[part 1 of 2: packages /Nexteer/NvMProxy_swc/DataTypes to /Nexteer/NvMProxy_swc/ComponentTypes]
AUTOSAR XML (schema 4-2-1)
package /Nexteer/NvMProxy_swc/DataTypes
  impl type NvM_BlockIdType: category=VALUE, base-type=NvM_BlockIdType, range raw 1..32767
  impl type NvM_RequestResultType: category=VALUE, base-type=NvM_RequestResultType, compu {0=NVM_REQ_OK, 1=NVM_REQ_NOT_OK, 2=NVM_REQ_PENDING, 3=NVM_REQ_INTEGRITY_FAILED, 4=NVM_REQ_BLOCK_SKIPPED, 5=NVM_REQ_NV_INVALIDATED, 6=NVM_REQ_CANCELED, 7=NVM_REQ_REDUNDANCY_FAILED, 8=NVM_REQ_RESTORED_FROM_ROM}
package /Nexteer/NvMProxy_swc/DataTypes/BaseTypes
  base type NvM_BlockIdType: category=FIXED_LENGTH, base-type-size=16, base-type-encoding=NONE, native-declaration=uint16
  base type NvM_RequestResultType: category=FIXED_LENGTH, base-type-size=8, base-type-encoding=NONE, native-declaration=uint8
package /Nexteer/NvMProxy_swc/Interfaces
  5 x client server interface, all with is-service=true:
    NvMAdministration
      operation SetBlockProtection: possible-error=NvMAdministration/E_NOT_OK
        arg ProtectionEnabled_Arg: type=boolean, direction=IN
      error E_NOT_OK: error-code=1
    NvMService_AC3_SRBS
      6 x operation, all with possible-error=NvMService_AC3_SRBS/E_NOT_OK:
        EraseBlock
        GetErrorStatus
          arg ErrorStatus_Arg: type=NvM_RequestResultType, direction=OUT
        InvalidateNvBlock
        ReadBlock
          arg DstPtr_Arg: type=dtRef_VOID, direction=IN
        SetRamBlockStatus
          arg RamBlockStatus_Arg: type=boolean, direction=IN
        WriteBlock
          arg SrcPtr_Arg: type=dtRef_const_VOID, direction=IN
      error E_NOT_OK: error-code=1
    NvMService_AC3_SRBS_Defs
      7 x operation, all with possible-error=NvMService_AC3_SRBS_Defs/E_NOT_OK:
        EraseBlock
        GetErrorStatus
          arg ErrorStatus_Arg: type=NvM_RequestResultType, direction=OUT
        InvalidateNvBlock
        ReadBlock
          arg DstPtr_Arg: type=dtRef_VOID, direction=IN
        RestoreBlockDefaults
          arg DstPtr_Arg: type=dtRef_VOID, direction=IN
        SetRamBlockStatus
          arg RamBlockStatus_Arg: type=boolean, direction=IN
        WriteBlock
          arg SrcPtr_Arg: type=dtRef_const_VOID, direction=IN
      error E_NOT_OK: error-code=1
    NvMService_AC3_SRBS_DS
      8 x operation, all with possible-error=NvMService_AC3_SRBS_DS/E_NOT_OK:
        EraseBlock
        GetDataIndex
          arg DataIndex_Arg: type=uint8, direction=OUT
        GetErrorStatus
          arg ErrorStatus_Arg: type=NvM_RequestResultType, direction=OUT
        InvalidateNvBlock
        ReadBlock
          arg DstPtr_Arg: type=dtRef_VOID, direction=IN
        SetDataIndex
          arg DataIndex_Arg: type=uint8, direction=IN
        SetRamBlockStatus
          arg RamBlockStatus_Arg: type=boolean, direction=IN
        WriteBlock
          arg SrcPtr_Arg: type=dtRef_const_VOID, direction=IN
      error E_NOT_OK: error-code=1
    NvMService_AC3_SRBS_DS_Defs
      9 x operation, all with possible-error=NvMService_AC3_SRBS_DS_Defs/E_NOT_OK:
        EraseBlock
        GetDataIndex
          arg DataIndex_Arg: type=uint8, direction=OUT
        GetErrorStatus
          arg ErrorStatus_Arg: type=NvM_RequestResultType, direction=OUT
        InvalidateNvBlock
        ReadBlock
          arg DstPtr_Arg: type=dtRef_VOID, direction=IN
        RestoreBlockDefaults
          arg DstPtr_Arg: type=dtRef_VOID, direction=IN
        SetDataIndex
          arg DataIndex_Arg: type=uint8, direction=IN
        SetRamBlockStatus
          arg RamBlockStatus_Arg: type=boolean, direction=IN
        WriteBlock
          arg SrcPtr_Arg: type=dtRef_const_VOID, direction=IN
      error E_NOT_OK: error-code=1
package /Nexteer/NvMProxy_swc/ComponentTypes
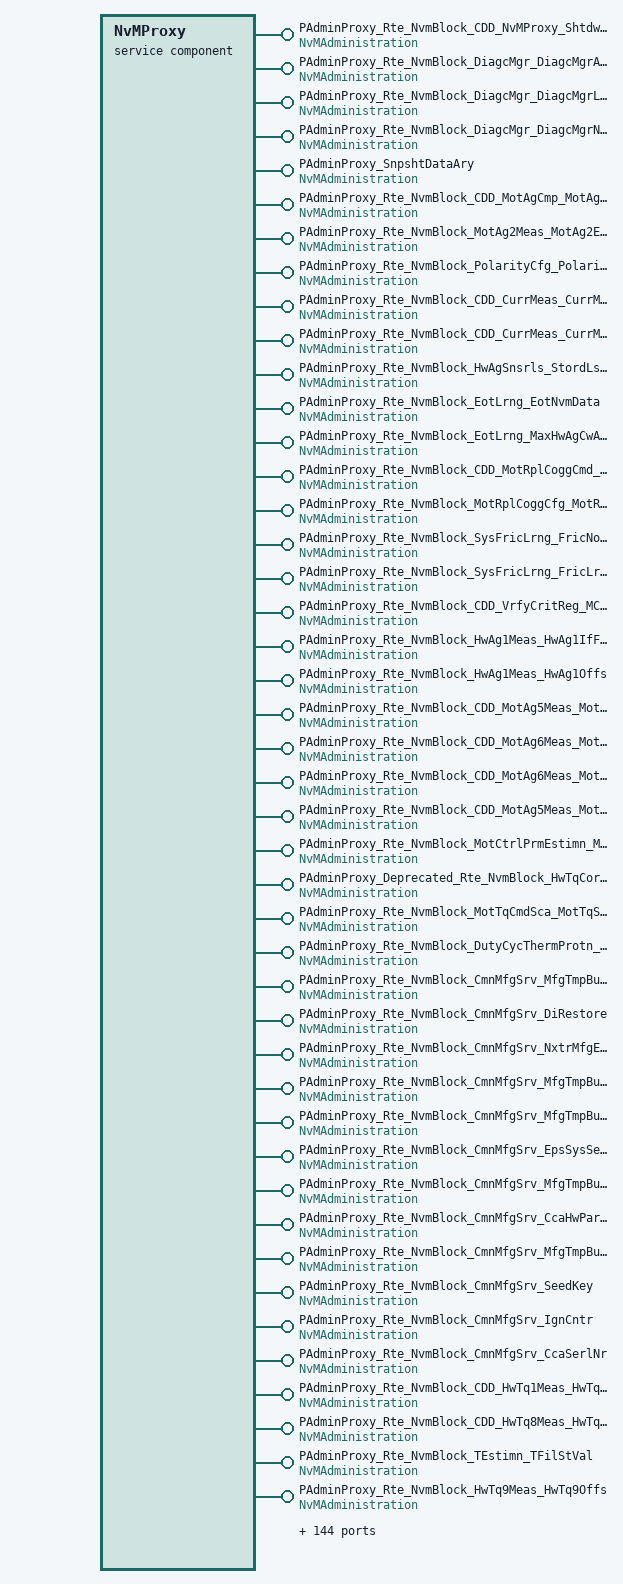
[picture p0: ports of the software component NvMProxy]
  service sw component type NvMProxy
    188 x provide port:
      PAdminProxy_Rte_NvmBlock_CDD_NvMProxy_ShtdwnClsChk: server-com-spec{operation=SetBlockProtection, queue-length=1}, provided-interface=NvMAdministration
      PAdminProxy_Rte_NvmBlock_DiagcMgr_DiagcMgrApplCrc: server-com-spec{operation=SetBlockProtection, queue-length=1}, provided-interface=NvMAdministration
      PAdminProxy_Rte_NvmBlock_DiagcMgr_DiagcMgrLtchCntrAry: server-com-spec{operation=SetBlockProtection, queue-length=1}, provided-interface=NvMAdministration
      PAdminProxy_Rte_NvmBlock_DiagcMgr_DiagcMgrNtcFltAry: server-com-spec{operation=SetBlockProtection, queue-length=1}, provided-interface=NvMAdministration
      PAdminProxy_SnpshtDataAry: server-com-spec{operation=SetBlockProtection, queue-length=1}, provided-interface=NvMAdministration
      PAdminProxy_Rte_NvmBlock_CDD_MotAgCmp_MotAgCmpMotAgBackEmf: server-com-spec{operation=SetBlockProtection, queue-length=1}, provided-interface=NvMAdministration
      PAdminProxy_Rte_NvmBlock_MotAg2Meas_MotAg2EolPrm: server-com-spec{operation=SetBlockProtection, queue-length=1}, provided-interface=NvMAdministration
      PAdminProxy_Rte_NvmBlock_PolarityCfg_PolarityCfgSaved: server-com-spec{operation=SetBlockProtection, queue-length=1}, provided-interface=NvMAdministration
      PAdminProxy_Rte_NvmBlock_CDD_CurrMeas_CurrMeasEolGainCalSetABC: server-com-spec{operation=SetBlockProtection, queue-length=1}, provided-interface=NvMAdministration
      PAdminProxy_Rte_NvmBlock_CDD_CurrMeas_CurrMeasEolOffsCalSetABC: server-com-spec{operation=SetBlockProtection, queue-length=1}, provided-interface=NvMAdministration
      PAdminProxy_Rte_NvmBlock_HwAgSnsrls_StordLstPrm: server-com-spec{operation=SetBlockProtection, queue-length=1}, provided-interface=NvMAdministration
      PAdminProxy_Rte_NvmBlock_EotLrng_EotNvmData: server-com-spec{operation=SetBlockProtection, queue-length=1}, provided-interface=NvMAdministration
      PAdminProxy_Rte_NvmBlock_EotLrng_MaxHwAgCwAndCcw: server-com-spec{operation=SetBlockProtection, queue-length=1}, provided-interface=NvMAdministration
      PAdminProxy_Rte_NvmBlock_CDD_MotRplCoggCmd_MotCoggCmdY: server-com-spec{operation=SetBlockProtection, queue-length=1}, provided-interface=NvMAdministration
      PAdminProxy_Rte_NvmBlock_MotRplCoggCfg_MotRplCoggPrm: server-com-spec{operation=SetBlockProtection, queue-length=1}, provided-interface=NvMAdministration
      PAdminProxy_Rte_NvmBlock_SysFricLrng_FricNonLrngData: server-com-spec{operation=SetBlockProtection, queue-length=1}, provided-interface=NvMAdministration
      PAdminProxy_Rte_NvmBlock_SysFricLrng_FricLrngData: server-com-spec{operation=SetBlockProtection, queue-length=1}, provided-interface=NvMAdministration
      PAdminProxy_Rte_NvmBlock_CDD_VrfyCritReg_MCalReadVrfyCritRegFltNvmInfo: server-com-spec{operation=SetBlockProtection, queue-length=1}, provided-interface=NvMAdministration
      PAdminProxy_Rte_NvmBlock_HwAg1Meas_HwAg1IfFltLtch: server-com-spec{operation=SetBlockProtection, queue-length=1}, provided-interface=NvMAdministration
      PAdminProxy_Rte_NvmBlock_HwAg1Meas_HwAg1Offs: server-com-spec{operation=SetBlockProtection, queue-length=1}, provided-interface=NvMAdministration
      PAdminProxy_Rte_NvmBlock_CDD_MotAg5Meas_MotAg5EolPrm: server-com-spec{operation=SetBlockProtection, queue-length=1}, provided-interface=NvMAdministration
      PAdminProxy_Rte_NvmBlock_CDD_MotAg6Meas_MotAg6StVari: server-com-spec{operation=SetBlockProtection, queue-length=1}, provided-interface=NvMAdministration
      PAdminProxy_Rte_NvmBlock_CDD_MotAg6Meas_MotAg6EolPrm: server-com-spec{operation=SetBlockProtection, queue-length=1}, provided-interface=NvMAdministration
      PAdminProxy_Rte_NvmBlock_CDD_MotAg5Meas_MotAg5StVari: server-com-spec{operation=SetBlockProtection, queue-length=1}, provided-interface=NvMAdministration
      PAdminProxy_Rte_NvmBlock_MotCtrlPrmEstimn_MotPrmNom: server-com-spec{operation=SetBlockProtection, queue-length=1}, provided-interface=NvMAdministration
      PAdminProxy_Deprecated_Rte_NvmBlock_HwTqCorrln_HwTqChACmnModCmpLpFilSt: server-com-spec{operation=SetBlockProtection, queue-length=1}, provided-interface=NvMAdministration
      PAdminProxy_Rte_NvmBlock_MotTqCmdSca_MotTqScaFac: server-com-spec{operation=SetBlockProtection, queue-length=1}, provided-interface=NvMAdministration
      PAdminProxy_Rte_NvmBlock_DutyCycThermProtn_FilStVal: server-com-spec{operation=SetBlockProtection, queue-length=1}, provided-interface=NvMAdministration
      PAdminProxy_Rte_NvmBlock_CmnMfgSrv_MfgTmpBuf1: server-com-spec{operation=SetBlockProtection, queue-length=1}, provided-interface=NvMAdministration
      PAdminProxy_Rte_NvmBlock_CmnMfgSrv_DiRestore: server-com-spec{operation=SetBlockProtection, queue-length=1}, provided-interface=NvMAdministration
      PAdminProxy_Rte_NvmBlock_CmnMfgSrv_NxtrMfgEnaCntr: server-com-spec{operation=SetBlockProtection, queue-length=1}, provided-interface=NvMAdministration
      PAdminProxy_Rte_NvmBlock_CmnMfgSrv_MfgTmpBuf0: server-com-spec{operation=SetBlockProtection, queue-length=1}, provided-interface=NvMAdministration
      PAdminProxy_Rte_NvmBlock_CmnMfgSrv_MfgTmpBuf3: server-com-spec{operation=SetBlockProtection, queue-length=1}, provided-interface=NvMAdministration
      PAdminProxy_Rte_NvmBlock_CmnMfgSrv_EpsSysSerlNr: server-com-spec{operation=SetBlockProtection, queue-length=1}, provided-interface=NvMAdministration
      PAdminProxy_Rte_NvmBlock_CmnMfgSrv_MfgTmpBuf2: server-com-spec{operation=SetBlockProtection, queue-length=1}, provided-interface=NvMAdministration
      PAdminProxy_Rte_NvmBlock_CmnMfgSrv_CcaHwPartNr: server-com-spec{operation=SetBlockProtection, queue-length=1}, provided-interface=NvMAdministration
      PAdminProxy_Rte_NvmBlock_CmnMfgSrv_MfgTmpBuf4: server-com-spec{operation=SetBlockProtection, queue-length=1}, provided-interface=NvMAdministration
      PAdminProxy_Rte_NvmBlock_CmnMfgSrv_SeedKey: server-com-spec{operation=SetBlockProtection, queue-length=1}, provided-interface=NvMAdministration
      PAdminProxy_Rte_NvmBlock_CmnMfgSrv_IgnCntr: server-com-spec{operation=SetBlockProtection, queue-length=1}, provided-interface=NvMAdministration
      PAdminProxy_Rte_NvmBlock_CmnMfgSrv_CcaSerlNr: server-com-spec{operation=SetBlockProtection, queue-length=1}, provided-interface=NvMAdministration
      PAdminProxy_Rte_NvmBlock_CDD_HwTq1Meas_HwTq1Offs: server-com-spec{operation=SetBlockProtection, queue-length=1}, provided-interface=NvMAdministration
      PAdminProxy_Rte_NvmBlock_CDD_HwTq8Meas_HwTq8Offs: server-com-spec{operation=SetBlockProtection, queue-length=1}, provided-interface=NvMAdministration
      PAdminProxy_Rte_NvmBlock_TEstimn_TFilStVal: server-com-spec{operation=SetBlockProtection, queue-length=1}, provided-interface=NvMAdministration
      PAdminProxy_Rte_NvmBlock_HwTq9Meas_HwTq9Offs: server-com-spec{operation=SetBlockProtection, queue-length=1}, provided-interface=NvMAdministration
      PAdminProxy_Rte_NvmBlock_HwTq10Meas_HwTq10Offs: server-com-spec{operation=SetBlockProtection, queue-length=1}, provided-interface=NvMAdministration
      PAdminProxy_Rte_NvmBlock_CustDiag_DidDE04: server-com-spec{operation=SetBlockProtection, queue-length=1}, provided-interface=NvMAdministration
      PAdminProxy_Rte_NvmBlock_CustDiag_DidDE02: server-com-spec{operation=SetBlockProtection, queue-length=1}, provided-interface=NvMAdministration
      PAdminProxy_Rte_NvmBlock_CustDiag_Did3003: server-com-spec{operation=SetBlockProtection, queue-length=1}, provided-interface=NvMAdministration
      PAdminProxy_Rte_NvmBlock_CustDiag_DidDE01: server-com-spec{operation=SetBlockProtection, queue-length=1}, provided-interface=NvMAdministration
      PAdminProxy_Rte_NvmBlock_CustDiag_DidEE01: server-com-spec{operation=SetBlockProtection, queue-length=1}, provided-interface=NvMAdministration
      PAdminProxy_Rte_NvmBlock_CustDiag_DidDE03: server-com-spec{operation=SetBlockProtection, queue-length=1}, provided-interface=NvMAdministration
      PAdminProxy_Rte_NvmBlock_CustDiag_DidDE00: server-com-spec{operation=SetBlockProtection, queue-length=1}, provided-interface=NvMAdministration
      PAdminProxy_Rte_NvmBlock_CustDiag_DidF113: server-com-spec{operation=SetBlockProtection, queue-length=1}, provided-interface=NvMAdministration
      PAdminProxy_Rte_NvmBlock_CustDiag_DidEE02: server-com-spec{operation=SetBlockProtection, queue-length=1}, provided-interface=NvMAdministration
      PAdminProxy_Rte_NvmBlock_CustDiag_DidF111: server-com-spec{operation=SetBlockProtection, queue-length=1}, provided-interface=NvMAdministration
      PAdminProxy_Rte_NvmBlock_FordHwAgArbn_PrevIgnCycVal: server-com-spec{operation=SetBlockProtection, queue-length=1}, provided-interface=NvMAdministration
      PAdminProxy_Rte_NvmBlock_FordHwAgArbn_NonAbsOffsVldFlg: server-com-spec{operation=SetBlockProtection, queue-length=1}, provided-interface=NvMAdministration
      PAdminProxy_Rte_NvmBlock_FordHwAgArbn_NonAbsOffs: server-com-spec{operation=SetBlockProtection, queue-length=1}, provided-interface=NvMAdministration
      PAdminProxy_Rte_NvmBlock_FordVehSpdArbn_FordVehTireCircum: server-com-spec{operation=SetBlockProtection, queue-length=1}, provided-interface=NvMAdministration
      PAdminProxy_Rte_NvmBlock_CustDiag_DidEE87: server-com-spec{operation=SetBlockProtection, queue-length=1}, provided-interface=NvMAdministration
      PAdminProxy_Rte_NvmBlock_CustDiag_DidF110: server-com-spec{operation=SetBlockProtection, queue-length=1}, provided-interface=NvMAdministration
      PAdminProxy_Rte_NvmBlock_CustDiag_DidF163: server-com-spec{operation=SetBlockProtection, queue-length=1}, provided-interface=NvMAdministration
      PAdminProxy_Rte_NvmBlock_CustDiag_DidF18C: server-com-spec{operation=SetBlockProtection, queue-length=1}, provided-interface=NvMAdministration
      PAdminProxy_Rte_NvmBlock_CustDiag_Did205B: server-com-spec{operation=SetBlockProtection, queue-length=1}, provided-interface=NvMAdministration
      PAdminProxy_Rte_NvmBlock_CustDiag_DidEE00: server-com-spec{operation=SetBlockProtection, queue-length=1}, provided-interface=NvMAdministration
      PAdminProxy_Rte_NvmBlock_CustDiag_DidDE05: server-com-spec{operation=SetBlockProtection, queue-length=1}, provided-interface=NvMAdministration
      PAdminProxy_Rte_NvmBlock_CustDiag_DidEE40: server-com-spec{operation=SetBlockProtection, queue-length=1}, provided-interface=NvMAdministration
      PAdminProxy_Rte_NvmBlock_CustDiag_DidF18A: server-com-spec{operation=SetBlockProtection, queue-length=1}, provided-interface=NvMAdministration
      PAdminProxy_Rte_NvmBlock_CustDiag_DidEE84: server-com-spec{operation=SetBlockProtection, queue-length=1}, provided-interface=NvMAdministration
      PAdminProxy_Rte_NvmBlock_CustDiag_DidF15F: server-com-spec{operation=SetBlockProtection, queue-length=1}, provided-interface=NvMAdministration
      PAdminProxy_Rte_NvmBlock_CustDiag_DidF166: server-com-spec{operation=SetBlockProtection, queue-length=1}, provided-interface=NvMAdministration
      PAdminProxy_Rte_NvmBlock_CustDiag_DidF162: server-com-spec{operation=SetBlockProtection, queue-length=1}, provided-interface=NvMAdministration
      PAdminProxy_Rte_NvmBlock_CustDiag_DidEE82: server-com-spec{operation=SetBlockProtection, queue-length=1}, provided-interface=NvMAdministration
      PAdminProxy_Rte_NvmBlock_CustDiag_DidEE86: server-com-spec{operation=SetBlockProtection, queue-length=1}, provided-interface=NvMAdministration
      PAdminProxy_Rte_NvmBlock_CustDiag_DidEE88: server-com-spec{operation=SetBlockProtection, queue-length=1}, provided-interface=NvMAdministration
      PAdminProxy_Rte_NvmBlock_CustDiag_DidEE85: server-com-spec{operation=SetBlockProtection, queue-length=1}, provided-interface=NvMAdministration
      PAdminProxy_Rte_NvmBlock_CustDiag_Did205A: server-com-spec{operation=SetBlockProtection, queue-length=1}, provided-interface=NvMAdministration
      PAdminProxy_Rte_NvmBlock_CustDiag_DidEE81: server-com-spec{operation=SetBlockProtection, queue-length=1}, provided-interface=NvMAdministration
      PAdminProxy_Rte_NvmBlock_CustDiag_Did301A: server-com-spec{operation=SetBlockProtection, queue-length=1}, provided-interface=NvMAdministration
      PAdminProxy_Rte_NvmBlock_CustDiag_DidEE41: server-com-spec{operation=SetBlockProtection, queue-length=1}, provided-interface=NvMAdministration
      PAdminProxy_Rte_NvmBlock_CustDiag_DidEE83: server-com-spec{operation=SetBlockProtection, queue-length=1}, provided-interface=NvMAdministration
      PAdminProxy_Rte_NvmBlock_CustDiag_DidEED0: server-com-spec{operation=SetBlockProtection, queue-length=1}, provided-interface=NvMAdministration
      PAdminProxy_Rte_NvmBlock_CustDiag_DidEE21: server-com-spec{operation=SetBlockProtection, queue-length=1}, provided-interface=NvMAdministration
      PAdminProxy_Rte_NvmBlock_CustDiag_Did630F: server-com-spec{operation=SetBlockProtection, queue-length=1}, provided-interface=NvMAdministration
      PAdminProxy_Rte_NvmBlock_CustDiag_DidEE22: server-com-spec{operation=SetBlockProtection, queue-length=1}, provided-interface=NvMAdministration
      PAdminProxy_Rte_NvmBlock_CustDiag_DidEE23: server-com-spec{operation=SetBlockProtection, queue-length=1}, provided-interface=NvMAdministration
      PAdminProxy_Rte_NvmBlock_CustDiag_Did630FChk: server-com-spec{operation=SetBlockProtection, queue-length=1}, provided-interface=NvMAdministration
      PAdminProxy_Rte_NvmBlock_CustDiag_DidF190: server-com-spec{operation=SetBlockProtection, queue-length=1}, provided-interface=NvMAdministration
      PAdminProxy_Rte_NvmBlock_StackMeas_StackMeasRes: server-com-spec{operation=SetBlockProtection, queue-length=1}, provided-interface=NvMAdministration
      PAdminProxy_Rte_NvmBlock_StackMeas_StackMeasApplCrc: server-com-spec{operation=SetBlockProtection, queue-length=1}, provided-interface=NvMAdministration
      PAdminProxy_Rte_NvmBlock_CDD_FordBlaBoxIfCmp1_LaneAssi: server-com-spec{operation=SetBlockProtection, queue-length=1}, provided-interface=NvMAdministration
      PAdminProxy_Rte_NvmBlock_CDD_FordBlaBoxIfCmp1_ActvNiblCtrl: server-com-spec{operation=SetBlockProtection, queue-length=1}, provided-interface=NvMAdministration
      PAdminProxy_Rte_NvmBlock_CDD_FordBlaBoxIfCmp1_TrlrBackupAssi: server-com-spec{operation=SetBlockProtection, queue-length=1}, provided-interface=NvMAdministration
      PAdminProxy_Rte_NvmBlock_CDD_FordBlaBoxIfCmp1_PullDriftCmp: server-com-spec{operation=SetBlockProtection, queue-length=1}, provided-interface=NvMAdministration
      PSProxy_Rte_NvmBlock_DiagcMgr_DiagcMgrApplCrc: provided-interface=NvMService_AC3_SRBS_Defs
        provided-com-specs:
          operation=NvMService_AC3_SRBS_Defs/EraseBlock, queue-length=1
          operation=NvMService_AC3_SRBS_Defs/GetErrorStatus, queue-length=1
          operation=NvMService_AC3_SRBS_Defs/InvalidateNvBlock, queue-length=1
          operation=NvMService_AC3_SRBS_Defs/ReadBlock, queue-length=1
          operation=NvMService_AC3_SRBS_Defs/RestoreBlockDefaults, queue-length=1
          operation=NvMService_AC3_SRBS_Defs/SetRamBlockStatus, queue-length=1
          operation=NvMService_AC3_SRBS_Defs/WriteBlock, queue-length=1
      PSProxy_Rte_NvmBlock_CDD_MotAgCmp_MotAgCmpMotAgBackEmf: provided-interface=NvMService_AC3_SRBS_Defs
        provided-com-specs:
          operation=NvMService_AC3_SRBS_Defs/EraseBlock, queue-length=1
          operation=NvMService_AC3_SRBS_Defs/GetErrorStatus, queue-length=1
          operation=NvMService_AC3_SRBS_Defs/InvalidateNvBlock, queue-length=1
          operation=NvMService_AC3_SRBS_Defs/ReadBlock, queue-length=1
          operation=NvMService_AC3_SRBS_Defs/RestoreBlockDefaults, queue-length=1
          operation=NvMService_AC3_SRBS_Defs/SetRamBlockStatus, queue-length=1
          operation=NvMService_AC3_SRBS_Defs/WriteBlock, queue-length=1
      PSProxy_Rte_NvmBlock_MotAg2Meas_MotAg2EolPrm: provided-interface=NvMService_AC3_SRBS_Defs
        provided-com-specs:
          operation=NvMService_AC3_SRBS_Defs/EraseBlock, queue-length=1
          operation=NvMService_AC3_SRBS_Defs/GetErrorStatus, queue-length=1
          operation=NvMService_AC3_SRBS_Defs/InvalidateNvBlock, queue-length=1
          operation=NvMService_AC3_SRBS_Defs/ReadBlock, queue-length=1
          operation=NvMService_AC3_SRBS_Defs/RestoreBlockDefaults, queue-length=1
          operation=NvMService_AC3_SRBS_Defs/SetRamBlockStatus, queue-length=1
          operation=NvMService_AC3_SRBS_Defs/WriteBlock, queue-length=1
      PSProxy_Rte_NvmBlock_PolarityCfg_PolarityCfgSaved: provided-interface=NvMService_AC3_SRBS_Defs
        provided-com-specs:
          operation=NvMService_AC3_SRBS_Defs/EraseBlock, queue-length=1
          operation=NvMService_AC3_SRBS_Defs/GetErrorStatus, queue-length=1
          operation=NvMService_AC3_SRBS_Defs/InvalidateNvBlock, queue-length=1
          operation=NvMService_AC3_SRBS_Defs/ReadBlock, queue-length=1
          operation=NvMService_AC3_SRBS_Defs/RestoreBlockDefaults, queue-length=1
          operation=NvMService_AC3_SRBS_Defs/SetRamBlockStatus, queue-length=1
          operation=NvMService_AC3_SRBS_Defs/WriteBlock, queue-length=1
      PSProxy_Rte_NvmBlock_CDD_CurrMeas_CurrMeasEolGainCalSetABC: provided-interface=NvMService_AC3_SRBS_Defs
        provided-com-specs:
          operation=NvMService_AC3_SRBS_Defs/EraseBlock, queue-length=1
          operation=NvMService_AC3_SRBS_Defs/GetErrorStatus, queue-length=1
          operation=NvMService_AC3_SRBS_Defs/InvalidateNvBlock, queue-length=1
          operation=NvMService_AC3_SRBS_Defs/ReadBlock, queue-length=1
          operation=NvMService_AC3_SRBS_Defs/RestoreBlockDefaults, queue-length=1
          operation=NvMService_AC3_SRBS_Defs/SetRamBlockStatus, queue-length=1
          operation=NvMService_AC3_SRBS_Defs/WriteBlock, queue-length=1
      PSProxy_Rte_NvmBlock_CDD_CurrMeas_CurrMeasEolOffsCalSetABC: provided-interface=NvMService_AC3_SRBS_Defs
        provided-com-specs:
          operation=NvMService_AC3_SRBS_Defs/EraseBlock, queue-length=1
          operation=NvMService_AC3_SRBS_Defs/GetErrorStatus, queue-length=1
          operation=NvMService_AC3_SRBS_Defs/InvalidateNvBlock, queue-length=1
          operation=NvMService_AC3_SRBS_Defs/ReadBlock, queue-length=1
          operation=NvMService_AC3_SRBS_Defs/RestoreBlockDefaults, queue-length=1
          operation=NvMService_AC3_SRBS_Defs/SetRamBlockStatus, queue-length=1
          operation=NvMService_AC3_SRBS_Defs/WriteBlock, queue-length=1
      PSProxy_Rte_NvmBlock_HwAgSnsrls_StordLstPrm: provided-interface=NvMService_AC3_SRBS_Defs
        provided-com-specs:
          operation=NvMService_AC3_SRBS_Defs/EraseBlock, queue-length=1
          operation=NvMService_AC3_SRBS_Defs/GetErrorStatus, queue-length=1
          operation=NvMService_AC3_SRBS_Defs/InvalidateNvBlock, queue-length=1
          operation=NvMService_AC3_SRBS_Defs/ReadBlock, queue-length=1
          operation=NvMService_AC3_SRBS_Defs/RestoreBlockDefaults, queue-length=1
          operation=NvMService_AC3_SRBS_Defs/SetRamBlockStatus, queue-length=1
          operation=NvMService_AC3_SRBS_Defs/WriteBlock, queue-length=1
      PSProxy_Rte_NvmBlock_SysFricLrng_FricNonLrngData: provided-interface=NvMService_AC3_SRBS_Defs
        provided-com-specs:
          operation=NvMService_AC3_SRBS_Defs/EraseBlock, queue-length=1
          operation=NvMService_AC3_SRBS_Defs/GetErrorStatus, queue-length=1
          operation=NvMService_AC3_SRBS_Defs/InvalidateNvBlock, queue-length=1
          operation=NvMService_AC3_SRBS_Defs/ReadBlock, queue-length=1
          operation=NvMService_AC3_SRBS_Defs/RestoreBlockDefaults, queue-length=1
          operation=NvMService_AC3_SRBS_Defs/SetRamBlockStatus, queue-length=1
          operation=NvMService_AC3_SRBS_Defs/WriteBlock, queue-length=1
      PSProxy_Rte_NvmBlock_SysFricLrng_FricLrngData: provided-interface=NvMService_AC3_SRBS_Defs
        provided-com-specs:
          operation=NvMService_AC3_SRBS_Defs/EraseBlock, queue-length=1
          operation=NvMService_AC3_SRBS_Defs/GetErrorStatus, queue-length=1
          operation=NvMService_AC3_SRBS_Defs/InvalidateNvBlock, queue-length=1
          operation=NvMService_AC3_SRBS_Defs/ReadBlock, queue-length=1
          operation=NvMService_AC3_SRBS_Defs/RestoreBlockDefaults, queue-length=1
          operation=NvMService_AC3_SRBS_Defs/SetRamBlockStatus, queue-length=1
          operation=NvMService_AC3_SRBS_Defs/WriteBlock, queue-length=1
      PSProxy_Rte_NvmBlock_CmnMfgSrv_NxtrMfgEnaCntr: provided-interface=NvMService_AC3_SRBS_Defs
        provided-com-specs:
          operation=NvMService_AC3_SRBS_Defs/EraseBlock, queue-length=1
          operation=NvMService_AC3_SRBS_Defs/GetErrorStatus, queue-length=1
          operation=NvMService_AC3_SRBS_Defs/InvalidateNvBlock, queue-length=1
          operation=NvMService_AC3_SRBS_Defs/ReadBlock, queue-length=1
          operation=NvMService_AC3_SRBS_Defs/RestoreBlockDefaults, queue-length=1
          operation=NvMService_AC3_SRBS_Defs/SetRamBlockStatus, queue-length=1
          operation=NvMService_AC3_SRBS_Defs/WriteBlock, queue-length=1
      PSProxy_Rte_NvmBlock_CmnMfgSrv_SeedKey: provided-interface=NvMService_AC3_SRBS_Defs
        provided-com-specs:
          operation=NvMService_AC3_SRBS_Defs/EraseBlock, queue-length=1
          operation=NvMService_AC3_SRBS_Defs/GetErrorStatus, queue-length=1
          operation=NvMService_AC3_SRBS_Defs/InvalidateNvBlock, queue-length=1
          operation=NvMService_AC3_SRBS_Defs/ReadBlock, queue-length=1
          operation=NvMService_AC3_SRBS_Defs/RestoreBlockDefaults, queue-length=1
          operation=NvMService_AC3_SRBS_Defs/SetRamBlockStatus, queue-length=1
          operation=NvMService_AC3_SRBS_Defs/WriteBlock, queue-length=1
      PSProxy_Rte_NvmBlock_CmnMfgSrv_IgnCntr: provided-interface=NvMService_AC3_SRBS_Defs
        provided-com-specs:
          operation=NvMService_AC3_SRBS_Defs/EraseBlock, queue-length=1
          operation=NvMService_AC3_SRBS_Defs/GetErrorStatus, queue-length=1
          operation=NvMService_AC3_SRBS_Defs/InvalidateNvBlock, queue-length=1
          operation=NvMService_AC3_SRBS_Defs/ReadBlock, queue-length=1
          operation=NvMService_AC3_SRBS_Defs/RestoreBlockDefaults, queue-length=1
          operation=NvMService_AC3_SRBS_Defs/SetRamBlockStatus, queue-length=1
          operation=NvMService_AC3_SRBS_Defs/WriteBlock, queue-length=1
      PSProxy_Rte_NvmBlock_CDD_HwTq1Meas_HwTq1Offs: provided-interface=NvMService_AC3_SRBS_Defs
        provided-com-specs:
          operation=NvMService_AC3_SRBS_Defs/EraseBlock, queue-length=1
          operation=NvMService_AC3_SRBS_Defs/GetErrorStatus, queue-length=1
          operation=NvMService_AC3_SRBS_Defs/InvalidateNvBlock, queue-length=1
          operation=NvMService_AC3_SRBS_Defs/ReadBlock, queue-length=1
          operation=NvMService_AC3_SRBS_Defs/RestoreBlockDefaults, queue-length=1
          operation=NvMService_AC3_SRBS_Defs/SetRamBlockStatus, queue-length=1
          operation=NvMService_AC3_SRBS_Defs/WriteBlock, queue-length=1
      PSProxy_Rte_NvmBlock_CDD_HwTq8Meas_HwTq8Offs: provided-interface=NvMService_AC3_SRBS_Defs
        provided-com-specs:
          operation=NvMService_AC3_SRBS_Defs/EraseBlock, queue-length=1
          operation=NvMService_AC3_SRBS_Defs/GetErrorStatus, queue-length=1
          operation=NvMService_AC3_SRBS_Defs/InvalidateNvBlock, queue-length=1
          operation=NvMService_AC3_SRBS_Defs/ReadBlock, queue-length=1
          operation=NvMService_AC3_SRBS_Defs/RestoreBlockDefaults, queue-length=1
          operation=NvMService_AC3_SRBS_Defs/SetRamBlockStatus, queue-length=1
          operation=NvMService_AC3_SRBS_Defs/WriteBlock, queue-length=1
      PSProxy_Rte_NvmBlock_CustDiag_DidDE04: provided-interface=NvMService_AC3_SRBS_Defs
        provided-com-specs:
          operation=NvMService_AC3_SRBS_Defs/EraseBlock, queue-length=1
          operation=NvMService_AC3_SRBS_Defs/GetErrorStatus, queue-length=1
          operation=NvMService_AC3_SRBS_Defs/InvalidateNvBlock, queue-length=1
          operation=NvMService_AC3_SRBS_Defs/ReadBlock, queue-length=1
          operation=NvMService_AC3_SRBS_Defs/RestoreBlockDefaults, queue-length=1
          operation=NvMService_AC3_SRBS_Defs/SetRamBlockStatus, queue-length=1
          operation=NvMService_AC3_SRBS_Defs/WriteBlock, queue-length=1
      PSProxy_Rte_NvmBlock_CustDiag_DidDE02: provided-interface=NvMService_AC3_SRBS_Defs
        provided-com-specs:
          operation=NvMService_AC3_SRBS_Defs/EraseBlock, queue-length=1
          operation=NvMService_AC3_SRBS_Defs/GetErrorStatus, queue-length=1
          operation=NvMService_AC3_SRBS_Defs/InvalidateNvBlock, queue-length=1
          operation=NvMService_AC3_SRBS_Defs/ReadBlock, queue-length=1
          operation=NvMService_AC3_SRBS_Defs/RestoreBlockDefaults, queue-length=1
          operation=NvMService_AC3_SRBS_Defs/SetRamBlockStatus, queue-length=1
          operation=NvMService_AC3_SRBS_Defs/WriteBlock, queue-length=1
      PSProxy_Rte_NvmBlock_CustDiag_Did3003: provided-interface=NvMService_AC3_SRBS_Defs
        provided-com-specs:
          operation=NvMService_AC3_SRBS_Defs/EraseBlock, queue-length=1
          operation=NvMService_AC3_SRBS_Defs/GetErrorStatus, queue-length=1
          operation=NvMService_AC3_SRBS_Defs/InvalidateNvBlock, queue-length=1
          operation=NvMService_AC3_SRBS_Defs/ReadBlock, queue-length=1
          operation=NvMService_AC3_SRBS_Defs/RestoreBlockDefaults, queue-length=1
          operation=NvMService_AC3_SRBS_Defs/SetRamBlockStatus, queue-length=1
          operation=NvMService_AC3_SRBS_Defs/WriteBlock, queue-length=1
      PSProxy_Rte_NvmBlock_CustDiag_DidDE01: provided-interface=NvMService_AC3_SRBS_Defs
        provided-com-specs:
          operation=NvMService_AC3_SRBS_Defs/EraseBlock, queue-length=1
          operation=NvMService_AC3_SRBS_Defs/GetErrorStatus, queue-length=1
          operation=NvMService_AC3_SRBS_Defs/InvalidateNvBlock, queue-length=1
          operation=NvMService_AC3_SRBS_Defs/ReadBlock, queue-length=1
          operation=NvMService_AC3_SRBS_Defs/RestoreBlockDefaults, queue-length=1
          operation=NvMService_AC3_SRBS_Defs/SetRamBlockStatus, queue-length=1
          operation=NvMService_AC3_SRBS_Defs/WriteBlock, queue-length=1
      PSProxy_Rte_NvmBlock_CustDiag_DidEE01: provided-interface=NvMService_AC3_SRBS_Defs
        provided-com-specs:
          operation=NvMService_AC3_SRBS_Defs/EraseBlock, queue-length=1
          operation=NvMService_AC3_SRBS_Defs/GetErrorStatus, queue-length=1
          operation=NvMService_AC3_SRBS_Defs/InvalidateNvBlock, queue-length=1
          operation=NvMService_AC3_SRBS_Defs/ReadBlock, queue-length=1
          operation=NvMService_AC3_SRBS_Defs/RestoreBlockDefaults, queue-length=1
          operation=NvMService_AC3_SRBS_Defs/SetRamBlockStatus, queue-length=1
          operation=NvMService_AC3_SRBS_Defs/WriteBlock, queue-length=1
      PSProxy_Rte_NvmBlock_CustDiag_DidDE03: provided-interface=NvMService_AC3_SRBS_Defs
        provided-com-specs:
          operation=NvMService_AC3_SRBS_Defs/EraseBlock, queue-length=1
          operation=NvMService_AC3_SRBS_Defs/GetErrorStatus, queue-length=1
          operation=NvMService_AC3_SRBS_Defs/InvalidateNvBlock, queue-length=1
          operation=NvMService_AC3_SRBS_Defs/ReadBlock, queue-length=1
          operation=NvMService_AC3_SRBS_Defs/RestoreBlockDefaults, queue-length=1
          operation=NvMService_AC3_SRBS_Defs/SetRamBlockStatus, queue-length=1
          operation=NvMService_AC3_SRBS_Defs/WriteBlock, queue-length=1
      PSProxy_Rte_NvmBlock_CustDiag_DidDE00: provided-interface=NvMService_AC3_SRBS_Defs
        provided-com-specs:
          operation=NvMService_AC3_SRBS_Defs/EraseBlock, queue-length=1
          operation=NvMService_AC3_SRBS_Defs/GetErrorStatus, queue-length=1
          operation=NvMService_AC3_SRBS_Defs/InvalidateNvBlock, queue-length=1
          operation=NvMService_AC3_SRBS_Defs/ReadBlock, queue-length=1
          operation=NvMService_AC3_SRBS_Defs/RestoreBlockDefaults, queue-length=1
          operation=NvMService_AC3_SRBS_Defs/SetRamBlockStatus, queue-length=1
          operation=NvMService_AC3_SRBS_Defs/WriteBlock, queue-length=1
      PSProxy_Rte_NvmBlock_CustDiag_DidF113: provided-interface=NvMService_AC3_SRBS_Defs
        provided-com-specs:
          operation=NvMService_AC3_SRBS_Defs/EraseBlock, queue-length=1
          operation=NvMService_AC3_SRBS_Defs/GetErrorStatus, queue-length=1
          operation=NvMService_AC3_SRBS_Defs/InvalidateNvBlock, queue-length=1
          operation=NvMService_AC3_SRBS_Defs/ReadBlock, queue-length=1
          operation=NvMService_AC3_SRBS_Defs/RestoreBlockDefaults, queue-length=1
          operation=NvMService_AC3_SRBS_Defs/SetRamBlockStatus, queue-length=1
          operation=NvMService_AC3_SRBS_Defs/WriteBlock, queue-length=1
      PSProxy_Rte_NvmBlock_CustDiag_DidEE02: provided-interface=NvMService_AC3_SRBS_Defs
        provided-com-specs:
          operation=NvMService_AC3_SRBS_Defs/EraseBlock, queue-length=1
          operation=NvMService_AC3_SRBS_Defs/GetErrorStatus, queue-length=1
          operation=NvMService_AC3_SRBS_Defs/InvalidateNvBlock, queue-length=1
          operation=NvMService_AC3_SRBS_Defs/ReadBlock, queue-length=1
          operation=NvMService_AC3_SRBS_Defs/RestoreBlockDefaults, queue-length=1
          operation=NvMService_AC3_SRBS_Defs/SetRamBlockStatus, queue-length=1
          operation=NvMService_AC3_SRBS_Defs/WriteBlock, queue-length=1
      PSProxy_Rte_NvmBlock_CustDiag_DidF111: provided-interface=NvMService_AC3_SRBS_Defs
        provided-com-specs:
          operation=NvMService_AC3_SRBS_Defs/EraseBlock, queue-length=1
          operation=NvMService_AC3_SRBS_Defs/GetErrorStatus, queue-length=1
          operation=NvMService_AC3_SRBS_Defs/InvalidateNvBlock, queue-length=1
          operation=NvMService_AC3_SRBS_Defs/ReadBlock, queue-length=1
          operation=NvMService_AC3_SRBS_Defs/RestoreBlockDefaults, queue-length=1
          operation=NvMService_AC3_SRBS_Defs/SetRamBlockStatus, queue-length=1
          operation=NvMService_AC3_SRBS_Defs/WriteBlock, queue-length=1
      PSProxy_Rte_NvmBlock_FordHwAgArbn_PrevIgnCycVal: provided-interface=NvMService_AC3_SRBS_Defs
        provided-com-specs:
          operation=NvMService_AC3_SRBS_Defs/EraseBlock, queue-length=1
          operation=NvMService_AC3_SRBS_Defs/GetErrorStatus, queue-length=1
          operation=NvMService_AC3_SRBS_Defs/InvalidateNvBlock, queue-length=1
          operation=NvMService_AC3_SRBS_Defs/ReadBlock, queue-length=1
          operation=NvMService_AC3_SRBS_Defs/RestoreBlockDefaults, queue-length=1
          operation=NvMService_AC3_SRBS_Defs/SetRamBlockStatus, queue-length=1
          operation=NvMService_AC3_SRBS_Defs/WriteBlock, queue-length=1
      PSProxy_Rte_NvmBlock_CustDiag_DidEE87: provided-interface=NvMService_AC3_SRBS_Defs
        provided-com-specs:
          operation=NvMService_AC3_SRBS_Defs/EraseBlock, queue-length=1
          operation=NvMService_AC3_SRBS_Defs/GetErrorStatus, queue-length=1
          operation=NvMService_AC3_SRBS_Defs/InvalidateNvBlock, queue-length=1
          operation=NvMService_AC3_SRBS_Defs/ReadBlock, queue-length=1
          operation=NvMService_AC3_SRBS_Defs/RestoreBlockDefaults, queue-length=1
          operation=NvMService_AC3_SRBS_Defs/SetRamBlockStatus, queue-length=1
          operation=NvMService_AC3_SRBS_Defs/WriteBlock, queue-length=1
      PSProxy_Rte_NvmBlock_CustDiag_DidF110: provided-interface=NvMService_AC3_SRBS_Defs
        provided-com-specs:
          operation=NvMService_AC3_SRBS_Defs/EraseBlock, queue-length=1
          operation=NvMService_AC3_SRBS_Defs/GetErrorStatus, queue-length=1
          operation=NvMService_AC3_SRBS_Defs/InvalidateNvBlock, queue-length=1
          operation=NvMService_AC3_SRBS_Defs/ReadBlock, queue-length=1
          operation=NvMService_AC3_SRBS_Defs/RestoreBlockDefaults, queue-length=1
          operation=NvMService_AC3_SRBS_Defs/SetRamBlockStatus, queue-length=1
          operation=NvMService_AC3_SRBS_Defs/WriteBlock, queue-length=1
      PSProxy_Rte_NvmBlock_CustDiag_DidF163: provided-interface=NvMService_AC3_SRBS_Defs
        provided-com-specs:
          operation=NvMService_AC3_SRBS_Defs/EraseBlock, queue-length=1
          operation=NvMService_AC3_SRBS_Defs/GetErrorStatus, queue-length=1
          operation=NvMService_AC3_SRBS_Defs/InvalidateNvBlock, queue-length=1
          operation=NvMService_AC3_SRBS_Defs/ReadBlock, queue-length=1
          operation=NvMService_AC3_SRBS_Defs/RestoreBlockDefaults, queue-length=1
          operation=NvMService_AC3_SRBS_Defs/SetRamBlockStatus, queue-length=1
          operation=NvMService_AC3_SRBS_Defs/WriteBlock, queue-length=1
      PSProxy_Rte_NvmBlock_CustDiag_DidF18C: provided-interface=NvMService_AC3_SRBS_Defs
        provided-com-specs:
          operation=NvMService_AC3_SRBS_Defs/EraseBlock, queue-length=1
          operation=NvMService_AC3_SRBS_Defs/GetErrorStatus, queue-length=1
          operation=NvMService_AC3_SRBS_Defs/InvalidateNvBlock, queue-length=1
          operation=NvMService_AC3_SRBS_Defs/ReadBlock, queue-length=1
          operation=NvMService_AC3_SRBS_Defs/RestoreBlockDefaults, queue-length=1
          operation=NvMService_AC3_SRBS_Defs/SetRamBlockStatus, queue-length=1
          operation=NvMService_AC3_SRBS_Defs/WriteBlock, queue-length=1
      PSProxy_Rte_NvmBlock_CustDiag_Did205B: provided-interface=NvMService_AC3_SRBS_Defs
        provided-com-specs:
          operation=NvMService_AC3_SRBS_Defs/EraseBlock, queue-length=1
          operation=NvMService_AC3_SRBS_Defs/GetErrorStatus, queue-length=1
          operation=NvMService_AC3_SRBS_Defs/InvalidateNvBlock, queue-length=1
          operation=NvMService_AC3_SRBS_Defs/ReadBlock, queue-length=1
          operation=NvMService_AC3_SRBS_Defs/RestoreBlockDefaults, queue-length=1
          operation=NvMService_AC3_SRBS_Defs/SetRamBlockStatus, queue-length=1
          operation=NvMService_AC3_SRBS_Defs/WriteBlock, queue-length=1
      PSProxy_Rte_NvmBlock_CustDiag_DidEE00: provided-interface=NvMService_AC3_SRBS_Defs
        provided-com-specs:
          operation=NvMService_AC3_SRBS_Defs/EraseBlock, queue-length=1
          operation=NvMService_AC3_SRBS_Defs/GetErrorStatus, queue-length=1
          operation=NvMService_AC3_SRBS_Defs/InvalidateNvBlock, queue-length=1
          operation=NvMService_AC3_SRBS_Defs/ReadBlock, queue-length=1
          operation=NvMService_AC3_SRBS_Defs/RestoreBlockDefaults, queue-length=1
          operation=NvMService_AC3_SRBS_Defs/SetRamBlockStatus, queue-length=1
          operation=NvMService_AC3_SRBS_Defs/WriteBlock, queue-length=1
      PSProxy_Rte_NvmBlock_CustDiag_DidDE05: provided-interface=NvMService_AC3_SRBS_Defs
        provided-com-specs:
          operation=NvMService_AC3_SRBS_Defs/EraseBlock, queue-length=1
          operation=NvMService_AC3_SRBS_Defs/GetErrorStatus, queue-length=1
          operation=NvMService_AC3_SRBS_Defs/InvalidateNvBlock, queue-length=1
          operation=NvMService_AC3_SRBS_Defs/ReadBlock, queue-length=1
          operation=NvMService_AC3_SRBS_Defs/RestoreBlockDefaults, queue-length=1
          operation=NvMService_AC3_SRBS_Defs/SetRamBlockStatus, queue-length=1
          operation=NvMService_AC3_SRBS_Defs/WriteBlock, queue-length=1
      PSProxy_Rte_NvmBlock_CustDiag_DidEE40: provided-interface=NvMService_AC3_SRBS_Defs
        provided-com-specs:
          operation=NvMService_AC3_SRBS_Defs/EraseBlock, queue-length=1
          operation=NvMService_AC3_SRBS_Defs/GetErrorStatus, queue-length=1
          operation=NvMService_AC3_SRBS_Defs/InvalidateNvBlock, queue-length=1
          operation=NvMService_AC3_SRBS_Defs/ReadBlock, queue-length=1
          operation=NvMService_AC3_SRBS_Defs/RestoreBlockDefaults, queue-length=1
          operation=NvMService_AC3_SRBS_Defs/SetRamBlockStatus, queue-length=1
          operation=NvMService_AC3_SRBS_Defs/WriteBlock, queue-length=1
      PSProxy_Rte_NvmBlock_CustDiag_DidF18A: provided-interface=NvMService_AC3_SRBS_Defs
        provided-com-specs:
          operation=NvMService_AC3_SRBS_Defs/EraseBlock, queue-length=1
          operation=NvMService_AC3_SRBS_Defs/GetErrorStatus, queue-length=1
          operation=NvMService_AC3_SRBS_Defs/InvalidateNvBlock, queue-length=1
          operation=NvMService_AC3_SRBS_Defs/ReadBlock, queue-length=1
          operation=NvMService_AC3_SRBS_Defs/RestoreBlockDefaults, queue-length=1
          operation=NvMService_AC3_SRBS_Defs/SetRamBlockStatus, queue-length=1
          operation=NvMService_AC3_SRBS_Defs/WriteBlock, queue-length=1
      PSProxy_Rte_NvmBlock_CustDiag_DidEE84: provided-interface=NvMService_AC3_SRBS_Defs
        provided-com-specs:
          operation=NvMService_AC3_SRBS_Defs/EraseBlock, queue-length=1
          operation=NvMService_AC3_SRBS_Defs/GetErrorStatus, queue-length=1
          operation=NvMService_AC3_SRBS_Defs/InvalidateNvBlock, queue-length=1
          operation=NvMService_AC3_SRBS_Defs/ReadBlock, queue-length=1
          operation=NvMService_AC3_SRBS_Defs/RestoreBlockDefaults, queue-length=1
          operation=NvMService_AC3_SRBS_Defs/SetRamBlockStatus, queue-length=1
          operation=NvMService_AC3_SRBS_Defs/WriteBlock, queue-length=1
      PSProxy_Rte_NvmBlock_CustDiag_DidF15F: provided-interface=NvMService_AC3_SRBS_Defs
        provided-com-specs:
          operation=NvMService_AC3_SRBS_Defs/EraseBlock, queue-length=1
          operation=NvMService_AC3_SRBS_Defs/GetErrorStatus, queue-length=1
          operation=NvMService_AC3_SRBS_Defs/InvalidateNvBlock, queue-length=1
          operation=NvMService_AC3_SRBS_Defs/ReadBlock, queue-length=1
          operation=NvMService_AC3_SRBS_Defs/RestoreBlockDefaults, queue-length=1
          operation=NvMService_AC3_SRBS_Defs/SetRamBlockStatus, queue-length=1
          operation=NvMService_AC3_SRBS_Defs/WriteBlock, queue-length=1
      PSProxy_Rte_NvmBlock_CustDiag_DidF166: provided-interface=NvMService_AC3_SRBS_Defs
        provided-com-specs:
          operation=NvMService_AC3_SRBS_Defs/EraseBlock, queue-length=1
          operation=NvMService_AC3_SRBS_Defs/GetErrorStatus, queue-length=1
          operation=NvMService_AC3_SRBS_Defs/InvalidateNvBlock, queue-length=1
          operation=NvMService_AC3_SRBS_Defs/ReadBlock, queue-length=1
          operation=NvMService_AC3_SRBS_Defs/RestoreBlockDefaults, queue-length=1
          operation=NvMService_AC3_SRBS_Defs/SetRamBlockStatus, queue-length=1
          operation=NvMService_AC3_SRBS_Defs/WriteBlock, queue-length=1
      PSProxy_Rte_NvmBlock_CustDiag_DidF162: provided-interface=NvMService_AC3_SRBS_Defs
        provided-com-specs:
          operation=NvMService_AC3_SRBS_Defs/EraseBlock, queue-length=1
          operation=NvMService_AC3_SRBS_Defs/GetErrorStatus, queue-length=1
          operation=NvMService_AC3_SRBS_Defs/InvalidateNvBlock, queue-length=1
          operation=NvMService_AC3_SRBS_Defs/ReadBlock, queue-length=1
          operation=NvMService_AC3_SRBS_Defs/RestoreBlockDefaults, queue-length=1
          operation=NvMService_AC3_SRBS_Defs/SetRamBlockStatus, queue-length=1
          operation=NvMService_AC3_SRBS_Defs/WriteBlock, queue-length=1
      PSProxy_Rte_NvmBlock_CustDiag_DidEE82: provided-interface=NvMService_AC3_SRBS_Defs
        provided-com-specs:
          operation=NvMService_AC3_SRBS_Defs/EraseBlock, queue-length=1
          operation=NvMService_AC3_SRBS_Defs/GetErrorStatus, queue-length=1
          operation=NvMService_AC3_SRBS_Defs/InvalidateNvBlock, queue-length=1
          operation=NvMService_AC3_SRBS_Defs/ReadBlock, queue-length=1
          operation=NvMService_AC3_SRBS_Defs/RestoreBlockDefaults, queue-length=1
          operation=NvMService_AC3_SRBS_Defs/SetRamBlockStatus, queue-length=1
          operation=NvMService_AC3_SRBS_Defs/WriteBlock, queue-length=1
      PSProxy_Rte_NvmBlock_CustDiag_DidEE86: provided-interface=NvMService_AC3_SRBS_Defs
        provided-com-specs:
          operation=NvMService_AC3_SRBS_Defs/EraseBlock, queue-length=1
          operation=NvMService_AC3_SRBS_Defs/GetErrorStatus, queue-length=1
          operation=NvMService_AC3_SRBS_Defs/InvalidateNvBlock, queue-length=1
          operation=NvMService_AC3_SRBS_Defs/ReadBlock, queue-length=1
          operation=NvMService_AC3_SRBS_Defs/RestoreBlockDefaults, queue-length=1
          operation=NvMService_AC3_SRBS_Defs/SetRamBlockStatus, queue-length=1
          operation=NvMService_AC3_SRBS_Defs/WriteBlock, queue-length=1
      PSProxy_Rte_NvmBlock_CustDiag_DidEE88: provided-interface=NvMService_AC3_SRBS_Defs
        provided-com-specs:
          operation=NvMService_AC3_SRBS_Defs/EraseBlock, queue-length=1
          operation=NvMService_AC3_SRBS_Defs/GetErrorStatus, queue-length=1
          operation=NvMService_AC3_SRBS_Defs/InvalidateNvBlock, queue-length=1
          operation=NvMService_AC3_SRBS_Defs/ReadBlock, queue-length=1
          operation=NvMService_AC3_SRBS_Defs/RestoreBlockDefaults, queue-length=1
          operation=NvMService_AC3_SRBS_Defs/SetRamBlockStatus, queue-length=1
          operation=NvMService_AC3_SRBS_Defs/WriteBlock, queue-length=1
      PSProxy_Rte_NvmBlock_CustDiag_DidEE85: provided-interface=NvMService_AC3_SRBS_Defs
        provided-com-specs:
          operation=NvMService_AC3_SRBS_Defs/EraseBlock, queue-length=1
          operation=NvMService_AC3_SRBS_Defs/GetErrorStatus, queue-length=1
          operation=NvMService_AC3_SRBS_Defs/InvalidateNvBlock, queue-length=1
          operation=NvMService_AC3_SRBS_Defs/ReadBlock, queue-length=1
          operation=NvMService_AC3_SRBS_Defs/RestoreBlockDefaults, queue-length=1
          operation=NvMService_AC3_SRBS_Defs/SetRamBlockStatus, queue-length=1
          operation=NvMService_AC3_SRBS_Defs/WriteBlock, queue-length=1
      PSProxy_Rte_NvmBlock_CustDiag_Did205A: provided-interface=NvMService_AC3_SRBS_Defs
        provided-com-specs:
          operation=NvMService_AC3_SRBS_Defs/EraseBlock, queue-length=1
          operation=NvMService_AC3_SRBS_Defs/GetErrorStatus, queue-length=1
          operation=NvMService_AC3_SRBS_Defs/InvalidateNvBlock, queue-length=1
          operation=NvMService_AC3_SRBS_Defs/ReadBlock, queue-length=1
          operation=NvMService_AC3_SRBS_Defs/RestoreBlockDefaults, queue-length=1
          operation=NvMService_AC3_SRBS_Defs/SetRamBlockStatus, queue-length=1
          operation=NvMService_AC3_SRBS_Defs/WriteBlock, queue-length=1
      PSProxy_Rte_NvmBlock_CustDiag_DidEE81: provided-interface=NvMService_AC3_SRBS_Defs
        provided-com-specs:
          operation=NvMService_AC3_SRBS_Defs/EraseBlock, queue-length=1
          operation=NvMService_AC3_SRBS_Defs/GetErrorStatus, queue-length=1
          operation=NvMService_AC3_SRBS_Defs/InvalidateNvBlock, queue-length=1
          operation=NvMService_AC3_SRBS_Defs/ReadBlock, queue-length=1
          operation=NvMService_AC3_SRBS_Defs/RestoreBlockDefaults, queue-length=1
          operation=NvMService_AC3_SRBS_Defs/SetRamBlockStatus, queue-length=1
          operation=NvMService_AC3_SRBS_Defs/WriteBlock, queue-length=1
      PSProxy_Rte_NvmBlock_CustDiag_Did301A: provided-interface=NvMService_AC3_SRBS_Defs
        provided-com-specs:
          operation=NvMService_AC3_SRBS_Defs/EraseBlock, queue-length=1
          operation=NvMService_AC3_SRBS_Defs/GetErrorStatus, queue-length=1
          operation=NvMService_AC3_SRBS_Defs/InvalidateNvBlock, queue-length=1
          operation=NvMService_AC3_SRBS_Defs/ReadBlock, queue-length=1
          operation=NvMService_AC3_SRBS_Defs/RestoreBlockDefaults, queue-length=1
          operation=NvMService_AC3_SRBS_Defs/SetRamBlockStatus, queue-length=1
          operation=NvMService_AC3_SRBS_Defs/WriteBlock, queue-length=1
      PSProxy_Rte_NvmBlock_CustDiag_DidEE41: provided-interface=NvMService_AC3_SRBS_Defs
        provided-com-specs:
          operation=NvMService_AC3_SRBS_Defs/EraseBlock, queue-length=1
          operation=NvMService_AC3_SRBS_Defs/GetErrorStatus, queue-length=1
          operation=NvMService_AC3_SRBS_Defs/InvalidateNvBlock, queue-length=1
          operation=NvMService_AC3_SRBS_Defs/ReadBlock, queue-length=1
          operation=NvMService_AC3_SRBS_Defs/RestoreBlockDefaults, queue-length=1
          operation=NvMService_AC3_SRBS_Defs/SetRamBlockStatus, queue-length=1
          operation=NvMService_AC3_SRBS_Defs/WriteBlock, queue-length=1
      PSProxy_Rte_NvmBlock_CustDiag_DidEE83: provided-interface=NvMService_AC3_SRBS_Defs
        provided-com-specs:
          operation=NvMService_AC3_SRBS_Defs/EraseBlock, queue-length=1
          operation=NvMService_AC3_SRBS_Defs/GetErrorStatus, queue-length=1
          operation=NvMService_AC3_SRBS_Defs/InvalidateNvBlock, queue-length=1
          operation=NvMService_AC3_SRBS_Defs/ReadBlock, queue-length=1
          operation=NvMService_AC3_SRBS_Defs/RestoreBlockDefaults, queue-length=1
          operation=NvMService_AC3_SRBS_Defs/SetRamBlockStatus, queue-length=1
          operation=NvMService_AC3_SRBS_Defs/WriteBlock, queue-length=1
      PSProxy_Rte_NvmBlock_CustDiag_DidEED0: provided-interface=NvMService_AC3_SRBS_Defs
        provided-com-specs:
          operation=NvMService_AC3_SRBS_Defs/EraseBlock, queue-length=1
          operation=NvMService_AC3_SRBS_Defs/GetErrorStatus, queue-length=1
          operation=NvMService_AC3_SRBS_Defs/InvalidateNvBlock, queue-length=1
          operation=NvMService_AC3_SRBS_Defs/ReadBlock, queue-length=1
          operation=NvMService_AC3_SRBS_Defs/RestoreBlockDefaults, queue-length=1
          operation=NvMService_AC3_SRBS_Defs/SetRamBlockStatus, queue-length=1
          operation=NvMService_AC3_SRBS_Defs/WriteBlock, queue-length=1
      PSProxy_Rte_NvmBlock_CustDiag_DidEE21: provided-interface=NvMService_AC3_SRBS_Defs
        provided-com-specs:
          operation=NvMService_AC3_SRBS_Defs/EraseBlock, queue-length=1
          operation=NvMService_AC3_SRBS_Defs/GetErrorStatus, queue-length=1
          operation=NvMService_AC3_SRBS_Defs/InvalidateNvBlock, queue-length=1
          operation=NvMService_AC3_SRBS_Defs/ReadBlock, queue-length=1
          operation=NvMService_AC3_SRBS_Defs/RestoreBlockDefaults, queue-length=1
          operation=NvMService_AC3_SRBS_Defs/SetRamBlockStatus, queue-length=1
          operation=NvMService_AC3_SRBS_Defs/WriteBlock, queue-length=1
      PSProxy_Rte_NvmBlock_CustDiag_Did630F: provided-interface=NvMService_AC3_SRBS_Defs
        provided-com-specs:
          operation=NvMService_AC3_SRBS_Defs/EraseBlock, queue-length=1
          operation=NvMService_AC3_SRBS_Defs/GetErrorStatus, queue-length=1
          operation=NvMService_AC3_SRBS_Defs/InvalidateNvBlock, queue-length=1
          operation=NvMService_AC3_SRBS_Defs/ReadBlock, queue-length=1
          operation=NvMService_AC3_SRBS_Defs/RestoreBlockDefaults, queue-length=1
          operation=NvMService_AC3_SRBS_Defs/SetRamBlockStatus, queue-length=1
          operation=NvMService_AC3_SRBS_Defs/WriteBlock, queue-length=1
      PSProxy_Rte_NvmBlock_CustDiag_DidEE22: provided-interface=NvMService_AC3_SRBS_Defs
        provided-com-specs:
          operation=NvMService_AC3_SRBS_Defs/EraseBlock, queue-length=1
          operation=NvMService_AC3_SRBS_Defs/GetErrorStatus, queue-length=1
          operation=NvMService_AC3_SRBS_Defs/InvalidateNvBlock, queue-length=1
          operation=NvMService_AC3_SRBS_Defs/ReadBlock, queue-length=1
          operation=NvMService_AC3_SRBS_Defs/RestoreBlockDefaults, queue-length=1
          operation=NvMService_AC3_SRBS_Defs/SetRamBlockStatus, queue-length=1
          operation=NvMService_AC3_SRBS_Defs/WriteBlock, queue-length=1
      PSProxy_Rte_NvmBlock_CustDiag_DidEE23: provided-interface=NvMService_AC3_SRBS_Defs
        provided-com-specs:
          operation=NvMService_AC3_SRBS_Defs/EraseBlock, queue-length=1
          operation=NvMService_AC3_SRBS_Defs/GetErrorStatus, queue-length=1
          operation=NvMService_AC3_SRBS_Defs/InvalidateNvBlock, queue-length=1
          operation=NvMService_AC3_SRBS_Defs/ReadBlock, queue-length=1
          operation=NvMService_AC3_SRBS_Defs/RestoreBlockDefaults, queue-length=1
          operation=NvMService_AC3_SRBS_Defs/SetRamBlockStatus, queue-length=1
          operation=NvMService_AC3_SRBS_Defs/WriteBlock, queue-length=1
      PSProxy_Rte_NvmBlock_CustDiag_Did630FChk: provided-interface=NvMService_AC3_SRBS_Defs
        provided-com-specs:
          operation=NvMService_AC3_SRBS_Defs/EraseBlock, queue-length=1
          operation=NvMService_AC3_SRBS_Defs/GetErrorStatus, queue-length=1
          operation=NvMService_AC3_SRBS_Defs/InvalidateNvBlock, queue-length=1
          operation=NvMService_AC3_SRBS_Defs/ReadBlock, queue-length=1
          operation=NvMService_AC3_SRBS_Defs/RestoreBlockDefaults, queue-length=1
          operation=NvMService_AC3_SRBS_Defs/SetRamBlockStatus, queue-length=1
          operation=NvMService_AC3_SRBS_Defs/WriteBlock, queue-length=1
      PSProxy_Rte_NvmBlock_CustDiag_DidF190: provided-interface=NvMService_AC3_SRBS_Defs
        provided-com-specs:
          operation=NvMService_AC3_SRBS_Defs/EraseBlock, queue-length=1
          operation=NvMService_AC3_SRBS_Defs/GetErrorStatus, queue-length=1
          operation=NvMService_AC3_SRBS_Defs/InvalidateNvBlock, queue-length=1
          operation=NvMService_AC3_SRBS_Defs/ReadBlock, queue-length=1
          operation=NvMService_AC3_SRBS_Defs/RestoreBlockDefaults, queue-length=1
          operation=NvMService_AC3_SRBS_Defs/SetRamBlockStatus, queue-length=1
          operation=NvMService_AC3_SRBS_Defs/WriteBlock, queue-length=1
      PSProxy_Rte_NvmBlock_StackMeas_StackMeasRes: provided-interface=NvMService_AC3_SRBS_Defs
        provided-com-specs:
          operation=NvMService_AC3_SRBS_Defs/EraseBlock, queue-length=1
          operation=NvMService_AC3_SRBS_Defs/GetErrorStatus, queue-length=1
          operation=NvMService_AC3_SRBS_Defs/InvalidateNvBlock, queue-length=1
          operation=NvMService_AC3_SRBS_Defs/ReadBlock, queue-length=1
          operation=NvMService_AC3_SRBS_Defs/RestoreBlockDefaults, queue-length=1
          operation=NvMService_AC3_SRBS_Defs/SetRamBlockStatus, queue-length=1
          operation=NvMService_AC3_SRBS_Defs/WriteBlock, queue-length=1
      PSProxy_Rte_NvmBlock_CDD_FordBlaBoxIfCmp1_LaneAssi: provided-interface=NvMService_AC3_SRBS_Defs
        provided-com-specs:
          operation=NvMService_AC3_SRBS_Defs/EraseBlock, queue-length=1
          operation=NvMService_AC3_SRBS_Defs/GetErrorStatus, queue-length=1
          operation=NvMService_AC3_SRBS_Defs/InvalidateNvBlock, queue-length=1
          operation=NvMService_AC3_SRBS_Defs/ReadBlock, queue-length=1
          operation=NvMService_AC3_SRBS_Defs/RestoreBlockDefaults, queue-length=1
          operation=NvMService_AC3_SRBS_Defs/SetRamBlockStatus, queue-length=1
          operation=NvMService_AC3_SRBS_Defs/WriteBlock, queue-length=1
      PSProxy_Rte_NvmBlock_CDD_FordBlaBoxIfCmp1_ActvNiblCtrl: provided-interface=NvMService_AC3_SRBS_Defs
        provided-com-specs:
          operation=NvMService_AC3_SRBS_Defs/EraseBlock, queue-length=1
          operation=NvMService_AC3_SRBS_Defs/GetErrorStatus, queue-length=1
          operation=NvMService_AC3_SRBS_Defs/InvalidateNvBlock, queue-length=1
          operation=NvMService_AC3_SRBS_Defs/ReadBlock, queue-length=1
          operation=NvMService_AC3_SRBS_Defs/RestoreBlockDefaults, queue-length=1
          operation=NvMService_AC3_SRBS_Defs/SetRamBlockStatus, queue-length=1
          operation=NvMService_AC3_SRBS_Defs/WriteBlock, queue-length=1
      PSProxy_Rte_NvmBlock_CDD_FordBlaBoxIfCmp1_TrlrBackupAssi: provided-interface=NvMService_AC3_SRBS_Defs
        provided-com-specs:
          operation=NvMService_AC3_SRBS_Defs/EraseBlock, queue-length=1
          operation=NvMService_AC3_SRBS_Defs/GetErrorStatus, queue-length=1
          operation=NvMService_AC3_SRBS_Defs/InvalidateNvBlock, queue-length=1
          operation=NvMService_AC3_SRBS_Defs/ReadBlock, queue-length=1
          operation=NvMService_AC3_SRBS_Defs/RestoreBlockDefaults, queue-length=1
          operation=NvMService_AC3_SRBS_Defs/SetRamBlockStatus, queue-length=1
          operation=NvMService_AC3_SRBS_Defs/WriteBlock, queue-length=1
      PSProxy_Rte_NvmBlock_CDD_FordBlaBoxIfCmp1_PullDriftCmp: provided-interface=NvMService_AC3_SRBS_Defs
        provided-com-specs:
          operation=NvMService_AC3_SRBS_Defs/EraseBlock, queue-length=1
          operation=NvMService_AC3_SRBS_Defs/GetErrorStatus, queue-length=1
          operation=NvMService_AC3_SRBS_Defs/InvalidateNvBlock, queue-length=1
          operation=NvMService_AC3_SRBS_Defs/ReadBlock, queue-length=1
          operation=NvMService_AC3_SRBS_Defs/RestoreBlockDefaults, queue-length=1
          operation=NvMService_AC3_SRBS_Defs/SetRamBlockStatus, queue-length=1
          operation=NvMService_AC3_SRBS_Defs/WriteBlock, queue-length=1
      PSProxy_Rte_NvmBlock_CDD_NvMProxy_ShtdwnClsChk: provided-interface=NvMService_AC3_SRBS
        provided-com-specs:
          operation=NvMService_AC3_SRBS/EraseBlock, queue-length=1
          operation=NvMService_AC3_SRBS/GetErrorStatus, queue-length=1
          operation=NvMService_AC3_SRBS/InvalidateNvBlock, queue-length=1
          operation=NvMService_AC3_SRBS/ReadBlock, queue-length=1
          operation=NvMService_AC3_SRBS/SetRamBlockStatus, queue-length=1
          operation=NvMService_AC3_SRBS/WriteBlock, queue-length=1
      PSProxy_Rte_NvmBlock_DiagcMgr_DiagcMgrLtchCntrAry: provided-interface=NvMService_AC3_SRBS
        provided-com-specs:
          operation=NvMService_AC3_SRBS/EraseBlock, queue-length=1
          operation=NvMService_AC3_SRBS/GetErrorStatus, queue-length=1
          operation=NvMService_AC3_SRBS/InvalidateNvBlock, queue-length=1
          operation=NvMService_AC3_SRBS/ReadBlock, queue-length=1
          operation=NvMService_AC3_SRBS/SetRamBlockStatus, queue-length=1
          operation=NvMService_AC3_SRBS/WriteBlock, queue-length=1
      PSProxy_Rte_NvmBlock_DiagcMgr_DiagcMgrNtcFltAry: provided-interface=NvMService_AC3_SRBS
        provided-com-specs:
          operation=NvMService_AC3_SRBS/EraseBlock, queue-length=1
          operation=NvMService_AC3_SRBS/GetErrorStatus, queue-length=1
          operation=NvMService_AC3_SRBS/InvalidateNvBlock, queue-length=1
          operation=NvMService_AC3_SRBS/ReadBlock, queue-length=1
          operation=NvMService_AC3_SRBS/SetRamBlockStatus, queue-length=1
          operation=NvMService_AC3_SRBS/WriteBlock, queue-length=1
      PSProxy_SnpshtDataAry: provided-interface=NvMService_AC3_SRBS
        provided-com-specs:
          operation=NvMService_AC3_SRBS/EraseBlock, queue-length=1
          operation=NvMService_AC3_SRBS/GetErrorStatus, queue-length=1
          operation=NvMService_AC3_SRBS/InvalidateNvBlock, queue-length=1
          operation=NvMService_AC3_SRBS/ReadBlock, queue-length=1
          operation=NvMService_AC3_SRBS/SetRamBlockStatus, queue-length=1
          operation=NvMService_AC3_SRBS/WriteBlock, queue-length=1
      PSProxy_Rte_NvmBlock_EotLrng_EotNvmData: provided-interface=NvMService_AC3_SRBS
        provided-com-specs:
          operation=NvMService_AC3_SRBS/EraseBlock, queue-length=1
          operation=NvMService_AC3_SRBS/GetErrorStatus, queue-length=1
          operation=NvMService_AC3_SRBS/InvalidateNvBlock, queue-length=1
          operation=NvMService_AC3_SRBS/ReadBlock, queue-length=1
          operation=NvMService_AC3_SRBS/SetRamBlockStatus, queue-length=1
          operation=NvMService_AC3_SRBS/WriteBlock, queue-length=1
      PSProxy_Rte_NvmBlock_EotLrng_MaxHwAgCwAndCcw: provided-interface=NvMService_AC3_SRBS
        provided-com-specs:
          operation=NvMService_AC3_SRBS/EraseBlock, queue-length=1
          operation=NvMService_AC3_SRBS/GetErrorStatus, queue-length=1
          operation=NvMService_AC3_SRBS/InvalidateNvBlock, queue-length=1
          operation=NvMService_AC3_SRBS/ReadBlock, queue-length=1
          operation=NvMService_AC3_SRBS/SetRamBlockStatus, queue-length=1
          operation=NvMService_AC3_SRBS/WriteBlock, queue-length=1
      PSProxy_Rte_NvmBlock_CDD_MotRplCoggCmd_MotCoggCmdY: provided-interface=NvMService_AC3_SRBS
        provided-com-specs:
          operation=NvMService_AC3_SRBS/EraseBlock, queue-length=1
          operation=NvMService_AC3_SRBS/GetErrorStatus, queue-length=1
          operation=NvMService_AC3_SRBS/InvalidateNvBlock, queue-length=1
          operation=NvMService_AC3_SRBS/ReadBlock, queue-length=1
          operation=NvMService_AC3_SRBS/SetRamBlockStatus, queue-length=1
          operation=NvMService_AC3_SRBS/WriteBlock, queue-length=1
      PSProxy_Rte_NvmBlock_MotRplCoggCfg_MotRplCoggPrm: provided-interface=NvMService_AC3_SRBS
        provided-com-specs:
          operation=NvMService_AC3_SRBS/EraseBlock, queue-length=1
          operation=NvMService_AC3_SRBS/GetErrorStatus, queue-length=1
          operation=NvMService_AC3_SRBS/InvalidateNvBlock, queue-length=1
          operation=NvMService_AC3_SRBS/ReadBlock, queue-length=1
          operation=NvMService_AC3_SRBS/SetRamBlockStatus, queue-length=1
          operation=NvMService_AC3_SRBS/WriteBlock, queue-length=1
      PSProxy_Rte_NvmBlock_CDD_VrfyCritReg_MCalReadVrfyCritRegFltNvmInfo: provided-interface=NvMService_AC3_SRBS
        provided-com-specs:
          operation=NvMService_AC3_SRBS/EraseBlock, queue-length=1
          operation=NvMService_AC3_SRBS/GetErrorStatus, queue-length=1
          operation=NvMService_AC3_SRBS/InvalidateNvBlock, queue-length=1
          operation=NvMService_AC3_SRBS/ReadBlock, queue-length=1
          operation=NvMService_AC3_SRBS/SetRamBlockStatus, queue-length=1
          operation=NvMService_AC3_SRBS/WriteBlock, queue-length=1
      PSProxy_Rte_NvmBlock_HwAg1Meas_HwAg1IfFltLtch: provided-interface=NvMService_AC3_SRBS
        provided-com-specs:
          operation=NvMService_AC3_SRBS/EraseBlock, queue-length=1
          operation=NvMService_AC3_SRBS/GetErrorStatus, queue-length=1
          operation=NvMService_AC3_SRBS/InvalidateNvBlock, queue-length=1
          operation=NvMService_AC3_SRBS/ReadBlock, queue-length=1
          operation=NvMService_AC3_SRBS/SetRamBlockStatus, queue-length=1
          operation=NvMService_AC3_SRBS/WriteBlock, queue-length=1
      PSProxy_Rte_NvmBlock_HwAg1Meas_HwAg1Offs: provided-interface=NvMService_AC3_SRBS
        provided-com-specs:
          operation=NvMService_AC3_SRBS/EraseBlock, queue-length=1
          operation=NvMService_AC3_SRBS/GetErrorStatus, queue-length=1
          operation=NvMService_AC3_SRBS/InvalidateNvBlock, queue-length=1
          operation=NvMService_AC3_SRBS/ReadBlock, queue-length=1
          operation=NvMService_AC3_SRBS/SetRamBlockStatus, queue-length=1
          operation=NvMService_AC3_SRBS/WriteBlock, queue-length=1
      PSProxy_Rte_NvmBlock_CDD_MotAg5Meas_MotAg5EolPrm: provided-interface=NvMService_AC3_SRBS
        provided-com-specs:
          operation=NvMService_AC3_SRBS/EraseBlock, queue-length=1
          operation=NvMService_AC3_SRBS/GetErrorStatus, queue-length=1
          operation=NvMService_AC3_SRBS/InvalidateNvBlock, queue-length=1
          operation=NvMService_AC3_SRBS/ReadBlock, queue-length=1
          operation=NvMService_AC3_SRBS/SetRamBlockStatus, queue-length=1
          operation=NvMService_AC3_SRBS/WriteBlock, queue-length=1
      PSProxy_Rte_NvmBlock_CDD_MotAg6Meas_MotAg6StVari: provided-interface=NvMService_AC3_SRBS
        provided-com-specs:
          operation=NvMService_AC3_SRBS/EraseBlock, queue-length=1
          operation=NvMService_AC3_SRBS/GetErrorStatus, queue-length=1
          operation=NvMService_AC3_SRBS/InvalidateNvBlock, queue-length=1
          operation=NvMService_AC3_SRBS/ReadBlock, queue-length=1
          operation=NvMService_AC3_SRBS/SetRamBlockStatus, queue-length=1
          operation=NvMService_AC3_SRBS/WriteBlock, queue-length=1
      PSProxy_Rte_NvmBlock_CDD_MotAg6Meas_MotAg6EolPrm: provided-interface=NvMService_AC3_SRBS
        provided-com-specs:
          operation=NvMService_AC3_SRBS/EraseBlock, queue-length=1
          operation=NvMService_AC3_SRBS/GetErrorStatus, queue-length=1
          operation=NvMService_AC3_SRBS/InvalidateNvBlock, queue-length=1
          operation=NvMService_AC3_SRBS/ReadBlock, queue-length=1
          operation=NvMService_AC3_SRBS/SetRamBlockStatus, queue-length=1
          operation=NvMService_AC3_SRBS/WriteBlock, queue-length=1
      PSProxy_Rte_NvmBlock_CDD_MotAg5Meas_MotAg5StVari: provided-interface=NvMService_AC3_SRBS
        provided-com-specs:
          operation=NvMService_AC3_SRBS/EraseBlock, queue-length=1
          operation=NvMService_AC3_SRBS/GetErrorStatus, queue-length=1
          operation=NvMService_AC3_SRBS/InvalidateNvBlock, queue-length=1
          operation=NvMService_AC3_SRBS/ReadBlock, queue-length=1
          operation=NvMService_AC3_SRBS/SetRamBlockStatus, queue-length=1
          operation=NvMService_AC3_SRBS/WriteBlock, queue-length=1
      PSProxy_Rte_NvmBlock_MotCtrlPrmEstimn_MotPrmNom: provided-interface=NvMService_AC3_SRBS
        provided-com-specs:
          operation=NvMService_AC3_SRBS/EraseBlock, queue-length=1
          operation=NvMService_AC3_SRBS/GetErrorStatus, queue-length=1
          operation=NvMService_AC3_SRBS/InvalidateNvBlock, queue-length=1
          operation=NvMService_AC3_SRBS/ReadBlock, queue-length=1
          operation=NvMService_AC3_SRBS/SetRamBlockStatus, queue-length=1
          operation=NvMService_AC3_SRBS/WriteBlock, queue-length=1
      PSProxy_Deprecated_Rte_NvmBlock_HwTqCorrln_HwTqChACmnModCmpLpFilSt: provided-interface=NvMService_AC3_SRBS
        provided-com-specs:
          operation=NvMService_AC3_SRBS/EraseBlock, queue-length=1
          operation=NvMService_AC3_SRBS/GetErrorStatus, queue-length=1
          operation=NvMService_AC3_SRBS/InvalidateNvBlock, queue-length=1
          operation=NvMService_AC3_SRBS/ReadBlock, queue-length=1
          operation=NvMService_AC3_SRBS/SetRamBlockStatus, queue-length=1
          operation=NvMService_AC3_SRBS/WriteBlock, queue-length=1
      PSProxy_Rte_NvmBlock_MotTqCmdSca_MotTqScaFac: provided-interface=NvMService_AC3_SRBS
        provided-com-specs:
          operation=NvMService_AC3_SRBS/EraseBlock, queue-length=1
          operation=NvMService_AC3_SRBS/GetErrorStatus, queue-length=1
          operation=NvMService_AC3_SRBS/InvalidateNvBlock, queue-length=1
          operation=NvMService_AC3_SRBS/ReadBlock, queue-length=1
          operation=NvMService_AC3_SRBS/SetRamBlockStatus, queue-length=1
          operation=NvMService_AC3_SRBS/WriteBlock, queue-length=1
      PSProxy_Rte_NvmBlock_DutyCycThermProtn_FilStVal: provided-interface=NvMService_AC3_SRBS
        provided-com-specs:
          operation=NvMService_AC3_SRBS/EraseBlock, queue-length=1
          operation=NvMService_AC3_SRBS/GetErrorStatus, queue-length=1
          operation=NvMService_AC3_SRBS/InvalidateNvBlock, queue-length=1
          operation=NvMService_AC3_SRBS/ReadBlock, queue-length=1
          operation=NvMService_AC3_SRBS/SetRamBlockStatus, queue-length=1
          operation=NvMService_AC3_SRBS/WriteBlock, queue-length=1
      PSProxy_Rte_NvmBlock_CmnMfgSrv_MfgTmpBuf1: provided-interface=NvMService_AC3_SRBS
        provided-com-specs:
          operation=NvMService_AC3_SRBS/EraseBlock, queue-length=1
          operation=NvMService_AC3_SRBS/GetErrorStatus, queue-length=1
          operation=NvMService_AC3_SRBS/InvalidateNvBlock, queue-length=1
          operation=NvMService_AC3_SRBS/ReadBlock, queue-length=1
          operation=NvMService_AC3_SRBS/SetRamBlockStatus, queue-length=1
          operation=NvMService_AC3_SRBS/WriteBlock, queue-length=1
      PSProxy_Rte_NvmBlock_CmnMfgSrv_DiRestore: provided-interface=NvMService_AC3_SRBS
        provided-com-specs:
          operation=NvMService_AC3_SRBS/EraseBlock, queue-length=1
          operation=NvMService_AC3_SRBS/GetErrorStatus, queue-length=1
          operation=NvMService_AC3_SRBS/InvalidateNvBlock, queue-length=1
          operation=NvMService_AC3_SRBS/ReadBlock, queue-length=1
          operation=NvMService_AC3_SRBS/SetRamBlockStatus, queue-length=1
          operation=NvMService_AC3_SRBS/WriteBlock, queue-length=1
      PSProxy_Rte_NvmBlock_CmnMfgSrv_MfgTmpBuf0: provided-interface=NvMService_AC3_SRBS
        provided-com-specs:
          operation=NvMService_AC3_SRBS/EraseBlock, queue-length=1
          operation=NvMService_AC3_SRBS/GetErrorStatus, queue-length=1
          operation=NvMService_AC3_SRBS/InvalidateNvBlock, queue-length=1
          operation=NvMService_AC3_SRBS/ReadBlock, queue-length=1
          operation=NvMService_AC3_SRBS/SetRamBlockStatus, queue-length=1
          operation=NvMService_AC3_SRBS/WriteBlock, queue-length=1
      PSProxy_Rte_NvmBlock_CmnMfgSrv_MfgTmpBuf3: provided-interface=NvMService_AC3_SRBS
        provided-com-specs:
          operation=NvMService_AC3_SRBS/EraseBlock, queue-length=1
          operation=NvMService_AC3_SRBS/GetErrorStatus, queue-length=1
          operation=NvMService_AC3_SRBS/InvalidateNvBlock, queue-length=1
          operation=NvMService_AC3_SRBS/ReadBlock, queue-length=1
          operation=NvMService_AC3_SRBS/SetRamBlockStatus, queue-length=1
          operation=NvMService_AC3_SRBS/WriteBlock, queue-length=1
      PSProxy_Rte_NvmBlock_CmnMfgSrv_EpsSysSerlNr: provided-interface=NvMService_AC3_SRBS
        provided-com-specs:
          operation=NvMService_AC3_SRBS/EraseBlock, queue-length=1
          operation=NvMService_AC3_SRBS/GetErrorStatus, queue-length=1
          operation=NvMService_AC3_SRBS/InvalidateNvBlock, queue-length=1
          operation=NvMService_AC3_SRBS/ReadBlock, queue-length=1
          operation=NvMService_AC3_SRBS/SetRamBlockStatus, queue-length=1
          operation=NvMService_AC3_SRBS/WriteBlock, queue-length=1
      PSProxy_Rte_NvmBlock_CmnMfgSrv_MfgTmpBuf2: provided-interface=NvMService_AC3_SRBS
        provided-com-specs:
          operation=NvMService_AC3_SRBS/EraseBlock, queue-length=1
          operation=NvMService_AC3_SRBS/GetErrorStatus, queue-length=1
          operation=NvMService_AC3_SRBS/InvalidateNvBlock, queue-length=1
          operation=NvMService_AC3_SRBS/ReadBlock, queue-length=1
          operation=NvMService_AC3_SRBS/SetRamBlockStatus, queue-length=1
          operation=NvMService_AC3_SRBS/WriteBlock, queue-length=1
      PSProxy_Rte_NvmBlock_CmnMfgSrv_CcaHwPartNr: provided-interface=NvMService_AC3_SRBS
        provided-com-specs:
          operation=NvMService_AC3_SRBS/EraseBlock, queue-length=1
          operation=NvMService_AC3_SRBS/GetErrorStatus, queue-length=1
          operation=NvMService_AC3_SRBS/InvalidateNvBlock, queue-length=1
          operation=NvMService_AC3_SRBS/ReadBlock, queue-length=1
          operation=NvMService_AC3_SRBS/SetRamBlockStatus, queue-length=1
          operation=NvMService_AC3_SRBS/WriteBlock, queue-length=1
      PSProxy_Rte_NvmBlock_CmnMfgSrv_MfgTmpBuf4: provided-interface=NvMService_AC3_SRBS
        provided-com-specs:
          operation=NvMService_AC3_SRBS/EraseBlock, queue-length=1
          operation=NvMService_AC3_SRBS/GetErrorStatus, queue-length=1
          operation=NvMService_AC3_SRBS/InvalidateNvBlock, queue-length=1
          operation=NvMService_AC3_SRBS/ReadBlock, queue-length=1
          operation=NvMService_AC3_SRBS/SetRamBlockStatus, queue-length=1
          operation=NvMService_AC3_SRBS/WriteBlock, queue-length=1
      PSProxy_Rte_NvmBlock_CmnMfgSrv_CcaSerlNr: provided-interface=NvMService_AC3_SRBS
        provided-com-specs:
          operation=NvMService_AC3_SRBS/EraseBlock, queue-length=1
          operation=NvMService_AC3_SRBS/GetErrorStatus, queue-length=1
          operation=NvMService_AC3_SRBS/InvalidateNvBlock, queue-length=1
          operation=NvMService_AC3_SRBS/ReadBlock, queue-length=1
          operation=NvMService_AC3_SRBS/SetRamBlockStatus, queue-length=1
          operation=NvMService_AC3_SRBS/WriteBlock, queue-length=1
      PSProxy_Rte_NvmBlock_TEstimn_TFilStVal: provided-interface=NvMService_AC3_SRBS
        provided-com-specs:
          operation=NvMService_AC3_SRBS/EraseBlock, queue-length=1
          operation=NvMService_AC3_SRBS/GetErrorStatus, queue-length=1
          operation=NvMService_AC3_SRBS/InvalidateNvBlock, queue-length=1
          operation=NvMService_AC3_SRBS/ReadBlock, queue-length=1
          operation=NvMService_AC3_SRBS/SetRamBlockStatus, queue-length=1
          operation=NvMService_AC3_SRBS/WriteBlock, queue-length=1
      PSProxy_Rte_NvmBlock_HwTq9Meas_HwTq9Offs: provided-interface=NvMService_AC3_SRBS
        provided-com-specs:
          operation=NvMService_AC3_SRBS/EraseBlock, queue-length=1
          operation=NvMService_AC3_SRBS/GetErrorStatus, queue-length=1
          operation=NvMService_AC3_SRBS/InvalidateNvBlock, queue-length=1
          operation=NvMService_AC3_SRBS/ReadBlock, queue-length=1
          operation=NvMService_AC3_SRBS/SetRamBlockStatus, queue-length=1
          operation=NvMService_AC3_SRBS/WriteBlock, queue-length=1
      PSProxy_Rte_NvmBlock_HwTq10Meas_HwTq10Offs: provided-interface=NvMService_AC3_SRBS
        provided-com-specs:
          operation=NvMService_AC3_SRBS/EraseBlock, queue-length=1
          operation=NvMService_AC3_SRBS/GetErrorStatus, queue-length=1
          operation=NvMService_AC3_SRBS/InvalidateNvBlock, queue-length=1
          operation=NvMService_AC3_SRBS/ReadBlock, queue-length=1
          operation=NvMService_AC3_SRBS/SetRamBlockStatus, queue-length=1
          operation=NvMService_AC3_SRBS/WriteBlock, queue-length=1
      PSProxy_Rte_NvmBlock_FordHwAgArbn_NonAbsOffsVldFlg: provided-interface=NvMService_AC3_SRBS
        provided-com-specs:
          operation=NvMService_AC3_SRBS/EraseBlock, queue-length=1
          operation=NvMService_AC3_SRBS/GetErrorStatus, queue-length=1
          operation=NvMService_AC3_SRBS/InvalidateNvBlock, queue-length=1
          operation=NvMService_AC3_SRBS/ReadBlock, queue-length=1
          operation=NvMService_AC3_SRBS/SetRamBlockStatus, queue-length=1
          operation=NvMService_AC3_SRBS/WriteBlock, queue-length=1
      PSProxy_Rte_NvmBlock_FordHwAgArbn_NonAbsOffs: provided-interface=NvMService_AC3_SRBS
        provided-com-specs:
          operation=NvMService_AC3_SRBS/EraseBlock, queue-length=1
          operation=NvMService_AC3_SRBS/GetErrorStatus, queue-length=1
          operation=NvMService_AC3_SRBS/InvalidateNvBlock, queue-length=1
          operation=NvMService_AC3_SRBS/ReadBlock, queue-length=1
          operation=NvMService_AC3_SRBS/SetRamBlockStatus, queue-length=1
          operation=NvMService_AC3_SRBS/WriteBlock, queue-length=1
      PSProxy_Rte_NvmBlock_FordVehSpdArbn_FordVehTireCircum: provided-interface=NvMService_AC3_SRBS
        provided-com-specs:
          operation=NvMService_AC3_SRBS/EraseBlock, queue-length=1
          operation=NvMService_AC3_SRBS/GetErrorStatus, queue-length=1
          operation=NvMService_AC3_SRBS/InvalidateNvBlock, queue-length=1
          operation=NvMService_AC3_SRBS/ReadBlock, queue-length=1
          operation=NvMService_AC3_SRBS/SetRamBlockStatus, queue-length=1
          operation=NvMService_AC3_SRBS/WriteBlock, queue-length=1
      PSProxy_Rte_NvmBlock_StackMeas_StackMeasApplCrc: provided-interface=NvMService_AC3_SRBS
        provided-com-specs:
          operation=NvMService_AC3_SRBS/EraseBlock, queue-length=1
          operation=NvMService_AC3_SRBS/GetErrorStatus, queue-length=1
          operation=NvMService_AC3_SRBS/InvalidateNvBlock, queue-length=1
          operation=NvMService_AC3_SRBS/ReadBlock, queue-length=1
          operation=NvMService_AC3_SRBS/SetRamBlockStatus, queue-length=1
          operation=NvMService_AC3_SRBS/WriteBlock, queue-length=1
